# STM32H7A3ZIT6Q register map
File version: 1.0
Registers are 32-bit, access not given, reset 0x0 unless marked. A register's access mark holds for its fields unless they carry their own. Offsets are from the block's base; [hi:lo] are bit positions; {n}, {i} and the like mark numbered series; 'fields as' and 'values as' point back to an identical list.

## RAMECC
Base 0x52009000
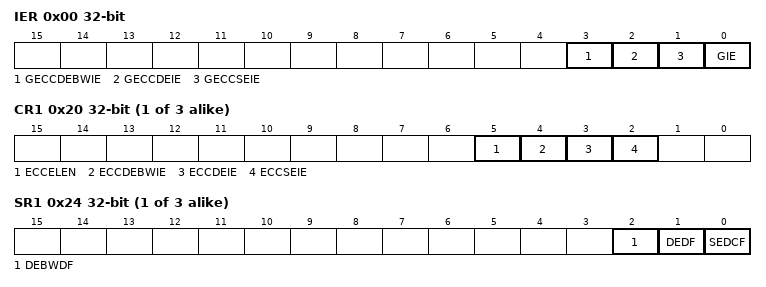
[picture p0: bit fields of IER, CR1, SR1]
0x00 IER
  [3] GECCDEBWIE, [2] GECCDEIE, [1] GECCSEIE, [0] GIE
{0x0+0x20*i} CR{i} (i=1..3)
  [5] ECCELEN, [4] ECCDEBWIE, [3] ECCDEIE, [2] ECCSEIE
{0x4+0x20*i} SR{i} (i=1..3)
  [2] DEBWDF, [1] DEDF, [0] SEDCF
{0x8+0x20*i} FAR{i} (i=1..3)
  [31:0] FDATAL
{0xC+0x20*i} FDRL{i} (i=1..3)
{0x10+0x20*i} FDRH{i} (i=1..3)
{0x14+0x20*i} FECR{i} (i=1..3)
  [31:0] FEC

## OCTOSPIM
Base 0x5200B400
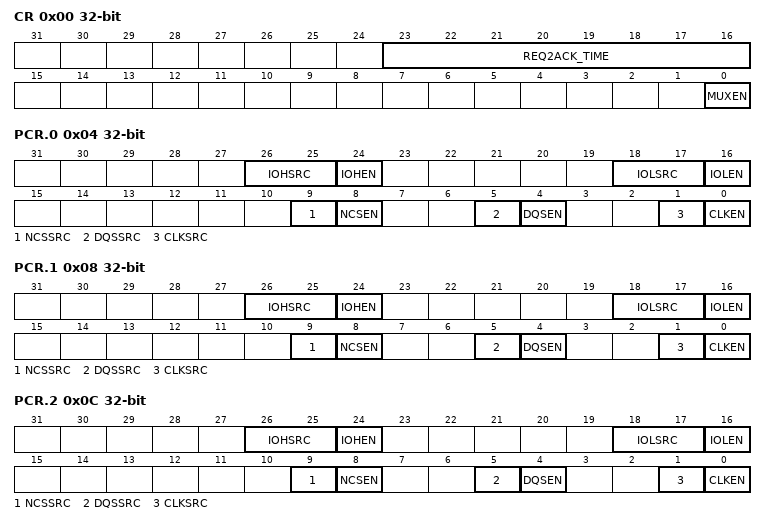
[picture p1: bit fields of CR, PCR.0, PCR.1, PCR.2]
0x00 CR
  [23:16] REQ2ACK_TIME, [0] MUXEN
0x04 PCR.0
  [26:25] IOHSRC, [24] IOHEN, [18:17] IOLSRC, [16] IOLEN, [9] NCSSRC, [8] NCSEN, [5] DQSSRC, [4] DQSEN, [1] CLKSRC, [0] CLKEN
0x08 PCR.1
  fields as PCR.0
0x0C PCR.2
  fields as PCR.0

## EXTI
Base 0x58000000
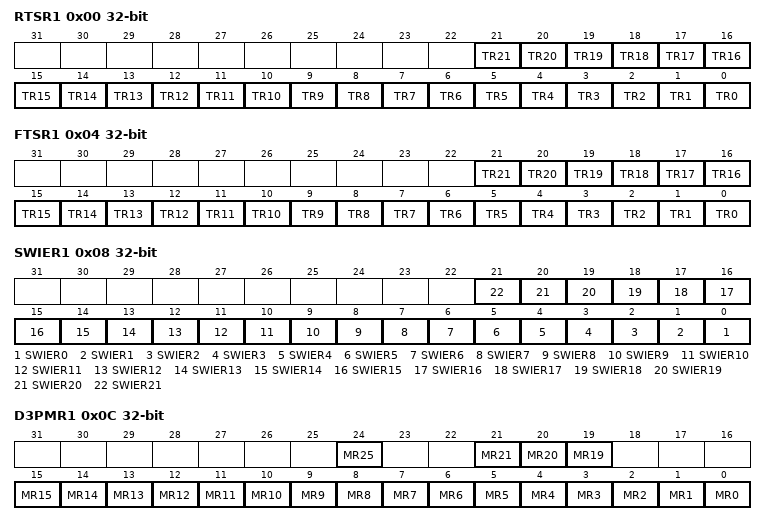
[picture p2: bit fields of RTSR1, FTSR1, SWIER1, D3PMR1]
0x00 RTSR1
  [n] TR{n} (n=0..21)
0x04 FTSR1
  [n] TR{n} (n=0..21)
0x08 SWIER1
  [n] SWIER{n} (n=0..21)
0x0C D3PMR1
  [24] MR25, [21] MR21, [20] MR20, [19] MR19, [n] MR{n} (n=0..15)
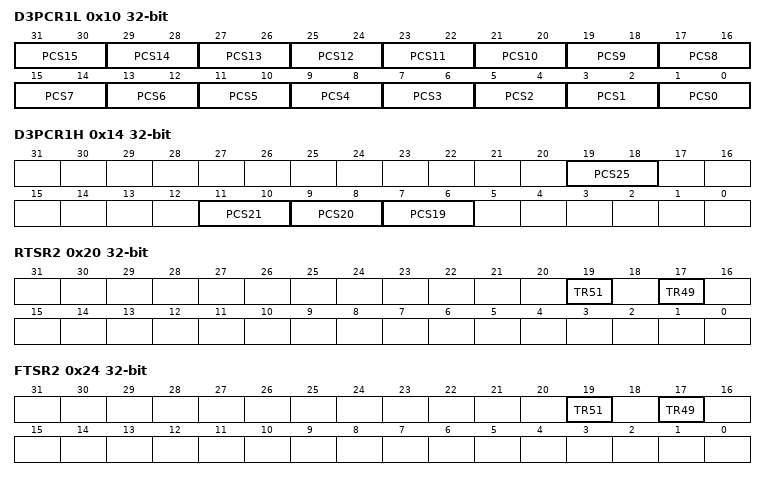
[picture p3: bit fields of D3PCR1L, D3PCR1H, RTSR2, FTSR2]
0x10 D3PCR1L
  [2n+1:2n] PCS{n} (n=0..15)
0x14 D3PCR1H
  [19:18] PCS25, [11:10] PCS21, [9:8] PCS20, [7:6] PCS19
0x20 RTSR2
  [19] TR51, [17] TR49
0x24 FTSR2
  [19] TR51, [17] TR49
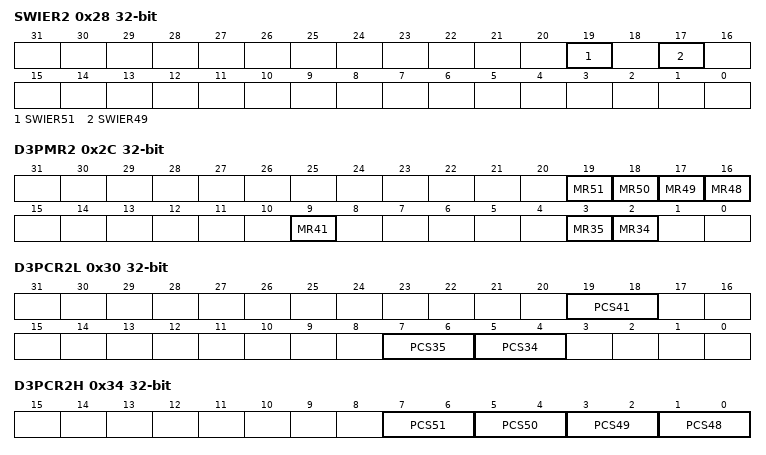
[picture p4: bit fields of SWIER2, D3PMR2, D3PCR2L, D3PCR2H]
0x28 SWIER2
  [19] SWIER51, [17] SWIER49
0x2C D3PMR2
  [n-32] MR{n} (n=48..51), [9] MR41, [3] MR35, [2] MR34
0x30 D3PCR2L
  [19:18] PCS41, [7:6] PCS35, [5:4] PCS34
0x34 D3PCR2H
  [2n-95:2n-96] PCS{n} (n=48..51)
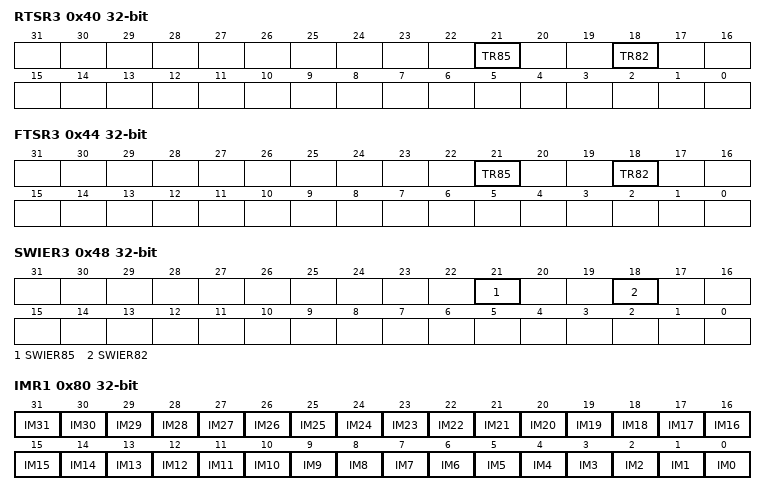
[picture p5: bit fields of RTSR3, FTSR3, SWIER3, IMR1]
0x40 RTSR3
  [21] TR85, [18] TR82
0x44 FTSR3
  [21] TR85, [18] TR82
0x48 SWIER3
  [21] SWIER85, [18] SWIER82
0x4C D3PMR3
  [24] MR88
0x50 D3PCR3L
0x54 D3PCR3H
  [17:16] PCS88
0x80 IMR1
  [n] IM{n} (n=0..31)
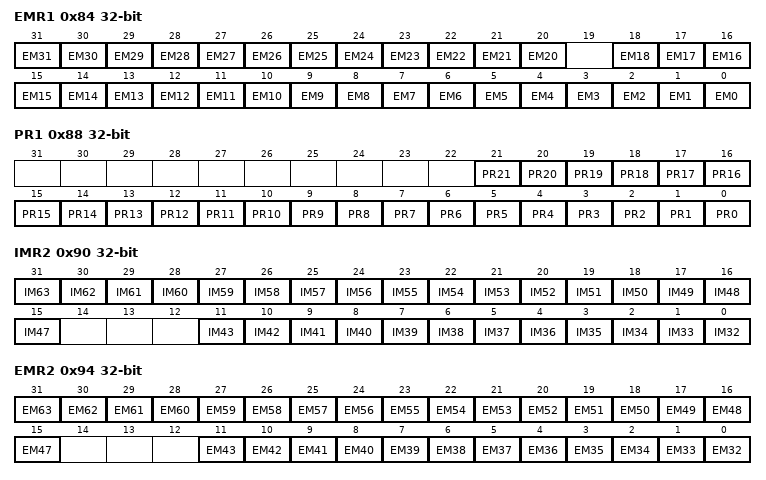
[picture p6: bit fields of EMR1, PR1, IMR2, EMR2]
0x84 EMR1
  [n] EM{n} (n=20..31), [n] EM{n} (n=0..18)
0x88 PR1
  [n] PR{n} (n=0..21)
0x90 IMR2
  [n-32] IM{n} (n=47..63), [n-32] IM{n} (n=32..43)
0x94 EMR2
  [n-32] EM{n} (n=47..63), [n-32] EM{n} (n=32..43)
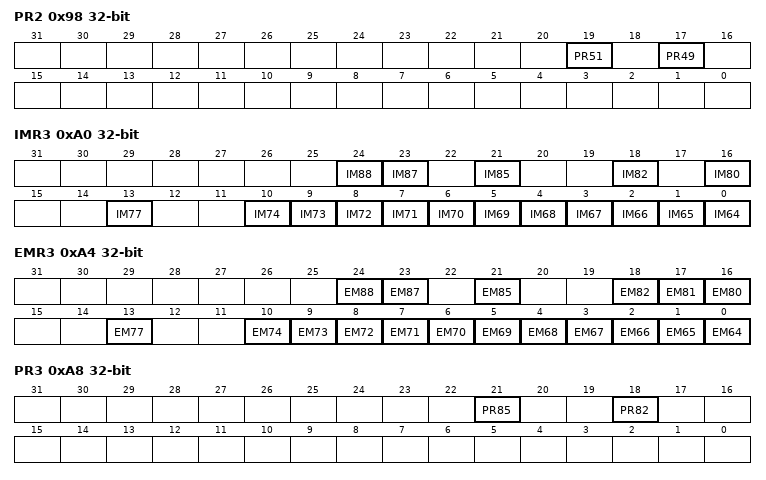
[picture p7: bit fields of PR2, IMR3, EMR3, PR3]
0x98 PR2
  [19] PR51, [17] PR49
0xA0 IMR3
  [24] IM88, [23] IM87, [21] IM85, [18] IM82, [16] IM80, [13] IM77, [n-64] IM{n} (n=64..74)
0xA4 EMR3
  [24] EM88, [23] EM87, [21] EM85, [18] EM82, [17] EM81, [16] EM80, [13] EM77, [n-64] EM{n} (n=64..74)
0xA8 PR3
  [21] PR85, [18] PR82

## EXTI_D1
Base 0x58000080
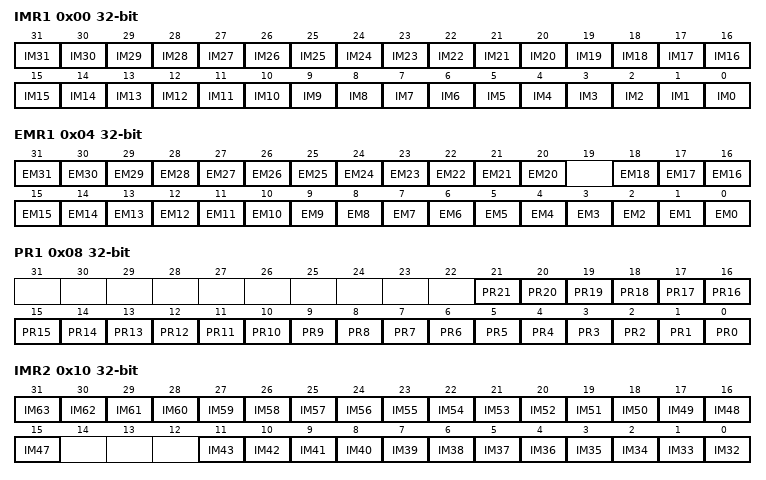
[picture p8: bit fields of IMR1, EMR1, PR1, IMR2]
0x00 IMR1
  [n] IM{n} (n=0..31)
0x04 EMR1
  [n] EM{n} (n=20..31), [n] EM{n} (n=0..18)
0x08 PR1
  [n] PR{n} (n=0..21)
0x10 IMR2
  [n-32] IM{n} (n=47..63), [n-32] IM{n} (n=32..43)
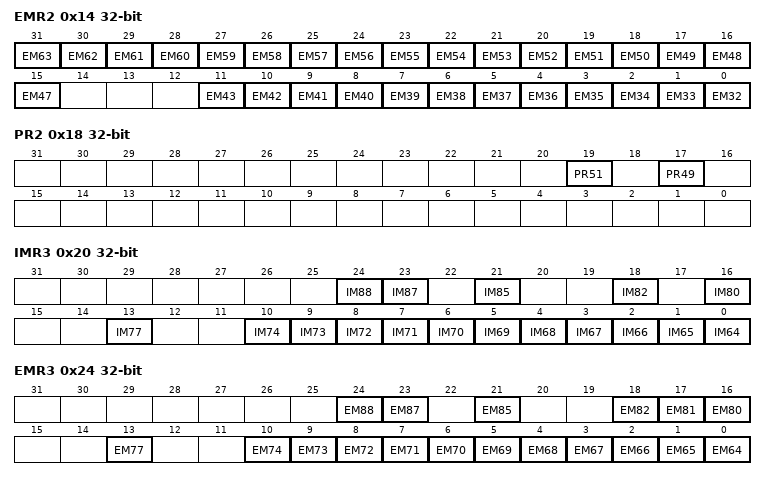
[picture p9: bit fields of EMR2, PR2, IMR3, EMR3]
0x14 EMR2
  [n-32] EM{n} (n=47..63), [n-32] EM{n} (n=32..43)
0x18 PR2
  [19] PR51, [17] PR49
0x20 IMR3
  [24] IM88, [23] IM87, [21] IM85, [18] IM82, [16] IM80, [13] IM77, [n-64] IM{n} (n=64..74)
0x24 EMR3
  [24] EM88, [23] EM87, [21] EM85, [18] EM82, [17] EM81, [16] EM80, [13] EM77, [n-64] EM{n} (n=64..74)
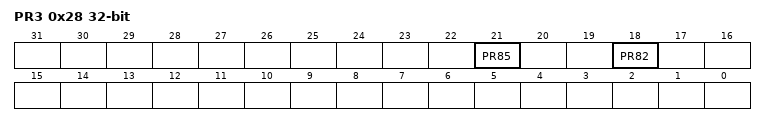
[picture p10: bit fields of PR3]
0x28 PR3
  [21] PR85, [18] PR82

## SYSCFG
Base 0x58000400
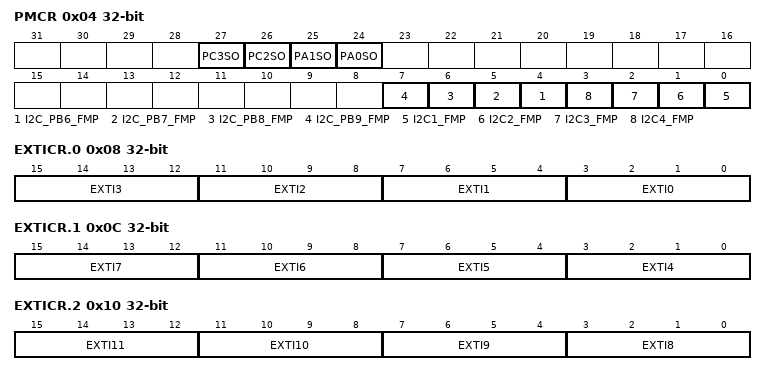
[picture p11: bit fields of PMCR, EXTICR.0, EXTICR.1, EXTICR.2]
0x04 PMCR
  [27] PC3SO, [26] PC2SO, [25] PA1SO, [24] PA0SO, [n-2] I2C_PB{n}_FMP (n=6..9), [n-1] I2C{n}_FMP (n=1..4)
0x08 EXTICR.0
  [4n+3:4n] EXTI{n} (n=0..3)
0x0C EXTICR.1
  [4n-13:4n-16] EXTI{n} (n=4..7)
0x10 EXTICR.2
  [4n-29:4n-32] EXTI{n} (n=8..11)
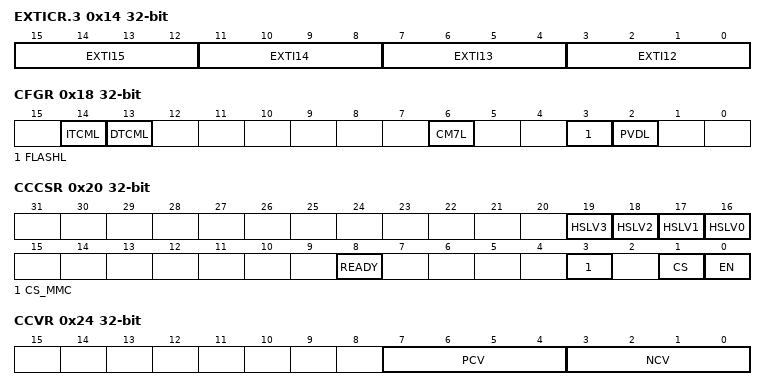
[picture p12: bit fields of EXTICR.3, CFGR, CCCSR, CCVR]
0x14 EXTICR.3
  [4n-45:4n-48] EXTI{n} (n=12..15)
0x18 CFGR
  [14] ITCML, [13] DTCML, [6] CM7L, [3] FLASHL, [2] PVDL
0x20 CCCSR
  [n+16] HSLV{n} (n=0..3), [8] READY, [3] CS_MMC, [1] CS, [0] EN
0x24 CCVR
  [7:4] PCV, [3:0] NCV
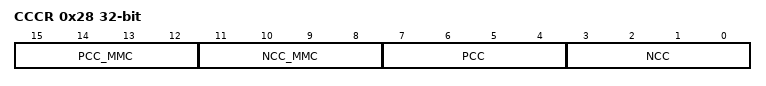
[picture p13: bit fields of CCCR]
0x28 CCCR
  [15:12] PCC_MMC, [11:8] NCC_MMC, [7:4] PCC, [3:0] NCC

## COMP12
Base 0x58003800
0x00 SR
0x04 ICFR
0x08 OR

## COMP1
Base 0x5800380C
Same registers: COMP2 0x58003810, COMP12_COMMON 0x58003810
0x00 CFGR

## VREFBUF
Base 0x58003C00
0x00 CSR
  [5] VRS_OUT3, [5:4] VRS_OUT4, [3] VRR, [1] HIZ, [0] ENVR
0x04 CCR
  [5:0] TRIM

## RTC
Base 0x58004000
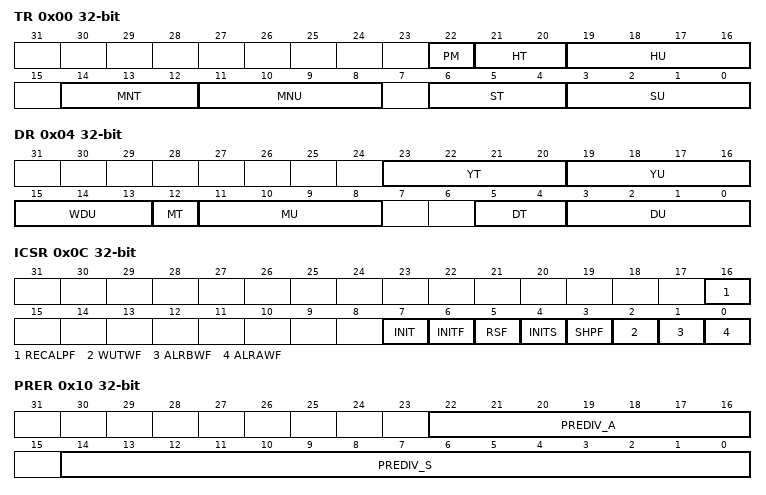
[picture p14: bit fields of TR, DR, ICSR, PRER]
0x00 TR
  [22] PM, [21:20] HT, [19:16] HU, [14:12] MNT, [11:8] MNU, [6:4] ST, [3:0] SU
0x04 DR
  [23:20] YT, [19:16] YU, [15:13] WDU, [12] MT, [11:8] MU, [5:4] DT, [3:0] DU
0x08 SSR
  [15:0] SS
0x0C ICSR
  [16] RECALPF, [7] INIT, [6] INITF, [5] RSF, [4] INITS, [3] SHPF, [2] WUTWF, [1] ALRBWF, [0] ALRAWF
0x10 PRER
  [22:16] PREDIV_A, [14:0] PREDIV_S
0x14 WUTR
  [15:0] WUT
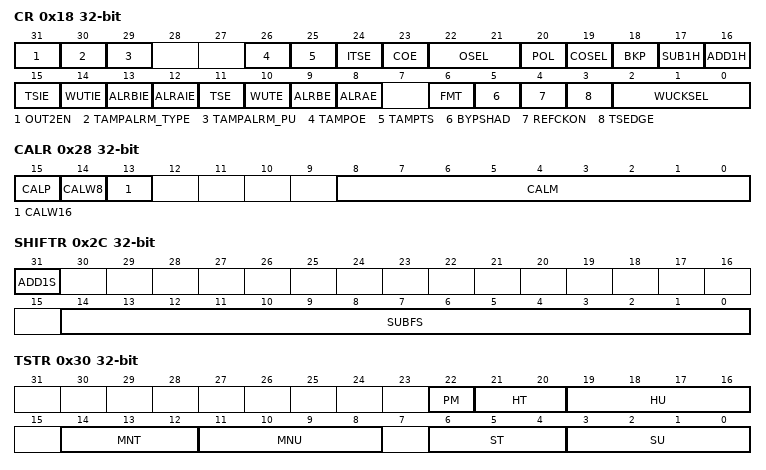
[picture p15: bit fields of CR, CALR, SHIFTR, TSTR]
0x18 CR
  [31] OUT2EN, [30] TAMPALRM_TYPE, [29] TAMPALRM_PU, [26] TAMPOE, [25] TAMPTS, [24] ITSE, [23] COE, [22:21] OSEL, [20] POL, [19] COSEL, [18] BKP, [17] SUB1H, [16] ADD1H, [15] TSIE, [14] WUTIE, [13] ALRBIE, [12] ALRAIE, [11] TSE, [10] WUTE, [9] ALRBE, [8] ALRAE, [6] FMT, [5] BYPSHAD, [4] REFCKON, [3] TSEDGE, [2:0] WUCKSEL
0x24 WPR
  [7:0] KEY
0x28 CALR
  [15] CALP, [14] CALW8, [13] CALW16, [8:0] CALM
0x2C SHIFTR
  [31] ADD1S, [14:0] SUBFS
0x30 TSTR
  fields as TR
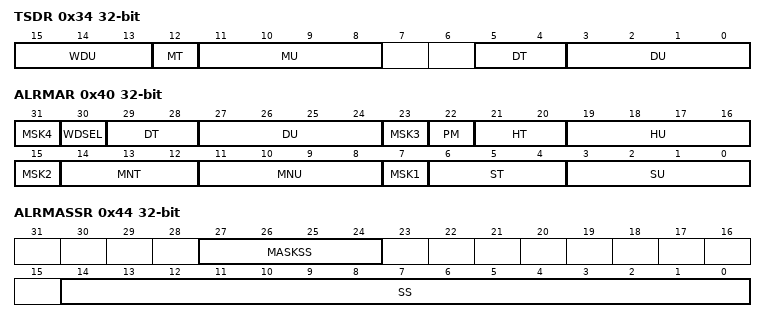
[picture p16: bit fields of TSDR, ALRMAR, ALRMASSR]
0x34 TSDR
  [15:13] WDU, [12] MT, [11:8] MU, [5:4] DT, [3:0] DU
0x38 TSSSR
  [15:0] SS
0x40 ALRMAR
  [8n-1] MSK{n} (n=1..4), [30] WDSEL, [29:28] DT, [27:24] DU, [22] PM, [21:20] HT, [19:16] HU, [14:12] MNT, [11:8] MNU, [6:4] ST, [3:0] SU
0x44 ALRMASSR
  [27:24] MASKSS, [14:0] SS
0x48 ALRMBR
  fields as ALRMAR
0x4C ALRMBSSR
  [27:24] MASKSS, [14:0] SS
0x50 SR
  [5] ITSF, [4] TSOVF, [3] TSF, [2] WUTF, [1] ALRBF, [0] ALRAF
0x54 MISR
  [5] ITSMF, [4] TSOVMF, [3] TSMF, [2] WUTMF, [1] ALRBMF, [0] ALRAMF
0x5C SCR
  [5] CITSF, [4] CTSOVF, [3] CTSF, [2] CWUTF, [1] CALRBF, [0] CALRAF
0x60 CFGR
